# AC7842x register map
Vendor: AutoChips; Series: AC78; File version: 1.0
CPU: CM4 r0p1, little endian, MPU, FPU, VTOR, 4 interrupt priority bits
Registers are 32-bit, read-write, reset 0x0 unless marked. A register's access mark holds for its fields unless they carry their own. Offsets are from the block's base; [hi:lo] are bit positions.

## FLASH — Embedded Flash
Base 0x40002000
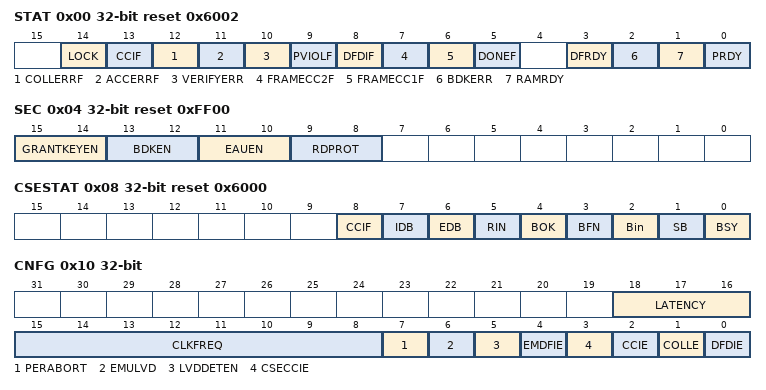
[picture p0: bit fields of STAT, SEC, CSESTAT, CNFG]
0x00 STAT reset 0x6002 (reset mask 0x0) — Flash status register
  [14] LOCK ro — Flash lock status
    0=Flash is unlocked; 1=Flash is locked
  [13] CCIF ro — Command completed flag
    0=Flash command is not completed; 1=Flash command is completed
  [12] COLLERRF — Collision error flag
    0=No collision error detected; 1=Collision error detected
  [11] ACCERRF — Error access flag
    0=No access error detected; 1=Access error detected
  [10] VERIFYERR — Verify flag
    0=No verify error detected; 1=Verify error detected
  [9] PVIOLF — Flash write protection violation flag
    0=No write protection error detected; 1=write protection error detected
  [8] DFDIF — Indicate FLASH ECC 2-bit error flag
    0=Not detected flash ECC 2-bit error; 1=Detected flash ECC 2-bit error
  [7] FRAMECC2F — Indicate flexRAM ECC 2-bit error flag
    0=Not detected flexRAM ECC 2-bit error; 1=Detected flexRAM ECC 2-bit error
  [6] FRAMECC1F — Indicate flexRAM ECC 1-bit error flag
    0=Not detected flexRAM ECC 1-bit error; 1=Detected flexRAM ECC 1-bit error
  [5] DONEF — Flash Command Complete status
    0=Command not complete; 1=Command complete
  [3] DFRDY ro — Indicate whether the D-Flash idle
    0=D-Flash not idle; 1=D-Flash idle
  [2] BDKERR ro — Indicate the backdoor key error for not match
    0=No backdoor key error; 1=Backdoor key error
  [1] RAMRDY ro — The current status of the FlexRAM
    0=FlexRAM is not avaliable for traditional RAM; 1=FlexRAM is avaliable for traditional RAM
  [0] PRDY ro — Partition ready flag
    0=CSE is busy or no partition; 1=Partition is ready
0x04 SEC ro reset 0xFF00 (reset mask 0x0) — MCU secure register
  [15:14] GRANTKEYEN — Grant key enable flag
    0=Grant key can not disable read protection; 1=Grant key can not disable read protection; 2=Grant key can not disable read protection; 3=Grant key can disable read protection
  [13:12] BDKEN — Backdoor key enable flag
    0=Backdoor key can disable read protection; 1=Backdoor key can disable read protection; 2=Backdoor key can disable read protection; 3=Backdoor key can not disable read protection
  [11:10] EAUEN — Erase all unsecure enable flag
    0=MDM control register can not send erase all unprotected operation; 1=MDM control register can not send erase all unprotected operation; 2=MDM control register can not send erase all unprotected operation; 3=MDM control register can send erase all unprotected operation
  [9:8] RDPROT — Read Protect
    0=read protect enable; 1=read protect enable; 2=read protect enable; 3=Read protect disable
0x08 CSESTAT reset 0x6000 (reset mask 0x0) — CSE status register
  [8] CCIF — CSE Command completed interrupt flag
    0=CSE command is not completed; 1=CSE command is completed
  [7] IDB ro — CSE internal debug
    0=CSE internal debugger functions disabled; 1=CSE internal debugger functions enabled
  [6] EDB ro — CSE external debug
    0=CSE external debugger not attached; 1=CSE external debugger is attached
  [5] RIN ro — CSE random number generator initialized
    0=CSE random number generator is not initialized; 1=CSE random number generator is initialized
  [4] BOK ro — CSE secure boot OK
    0=CSE secure boot is not completed, or seccure boot failure; 1=CSE secure boot was successful
  [3] BFN ro — CSE secure boot finished
    0=CSE secure boot is not finished; 1=CSE secure boot has finished
  [2] Bin ro — CSE secure boot initialization
    0=CSE secure boot personalization not completed; 1=CSE secure boot personalization has completed
  [1] SB ro — CSE secure boot status
    0=CSE secure boot not activated; 1=CSE secure boot activated
  [0] BSY ro — CSE busy status
    0=CSE command processing has completed; 1=CSE command processsing is in progress
0x0C KEYUNLK reset not defined — Flash unlock register
  [31:0] KEY — unlock flash key value
0x10 CNFG (reset mask 0x3000) — Flash configure register
  [18:16] LATENCY — read latency
    3=flash_clk less than 58MHz; 4=flash_clk is between 58MHz and 85MHz; 5=flash_clk is between 85MHz and 132MHz
  [15:8] CLKFREQ — Flash clock frequency
  [7] PERABORT — Abort page erase
    0=Abort page erase; 1=Not abort page erase
  [6] EMULVD — Emulation LVD enable
    0=Disable; 1=Enable
  [5] LVDDETEN — LVD detect enable
    0=Disable LVD detect; 1=Enable LVD detected
  [4] EMDFIE — Emulated flash ECC fault interrupt enable
    0=Disable emulated flash ECC fault interrupt; 1=Enable emulated flash ECC fault interrupt
  [3] CSECCIE — Enable CSE command completed interrupt
    0=Disable CSE command complete interrupt; 1=Enable CSE command complete interrupt
  [2] CCIE — Enable the command completed interrupt
    0=Disable flash command complete interrupt; 1=Enable flash command complete interrupt
  [1] COLLE — Enable flash collision interrupt
    0=Disable flash ccollision interrupt; 1=Enable flash ccollision interrupt
  [0] DFDIE — Enable flash ECC 2-bit error interrupt
    0=Disable flash ECC 2-bit error interrupt; 1=Enable flash ECC 2-bit error interrupt
0x14 CMD reset not defined — Flash command ID register
  [31:0] CMD — Flash command ID
0x18 ADDR reset not defined — Flash address register
  [31:0] ADDR — Flash address
0x1C DATA0 reset not defined — Flash data register 0
  [31:0] DATA0 — Flash data 0
0x20 DATA1 reset not defined — Flash data register 1
  [31:0] DATA1 — Flash data 1
0x24 LEN reset not defined — Flash length register
  [31:0] LEN — Flash length
0x30 CST reset not defined — Flash command start register
  [0] START — Flash start register
    0=Not trigger command; 1=Trigger command
0x34 PPROT reset 0xFFFFFFFF (reset mask 0x0) — P-Flash write protection register
  [31:0] PPROT — P-Flash write protection
0x38 DPROT reset 0xFF (reset mask 0x0) — D-Flash write protection register
  [7:0] DPROT — Flash D-Flash write protection
0x40 DFADR reset not defined — Flash ECC 2-bit error address register
  [31:0] DFADR — Flash ECC 2-bit error address
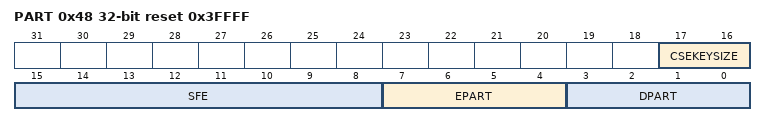
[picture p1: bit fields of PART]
0x48 PART ro reset 0x3FFFF (reset mask 0x0) — CSE partition information register
  [17:16] CSEKEYSIZE
    0=CSE key size is zero; 1=CSE key size is 128 bytes; 2=CSE key size is 256 bytes; 3=CSE key size is 512 bytes
  [15:8] SFE
  [7:4] EPART — FlexRAM partition inforamtion
    2=FlexRAM partition to 4KB for CSE access; 15=FlexRAM partition can't for CSE access
  [3:0] DPART — D-Flash partition information
    8=CSE backup area size is 64KB; 15=CSE backup area size 0KB
0x84 SWAPST ro reset 0x1 (reset mask 0x0) — Flash Swap status register
  [0] SWAP_FLAG
    0=SWAP B; 1=SWAP A
